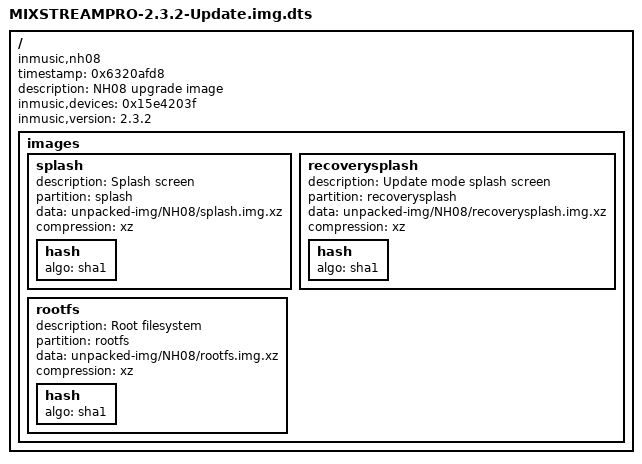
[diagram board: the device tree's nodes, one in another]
/dts-v1/;

/ {
	timestamp = <0x6320afd8>;
	description = "NH08 upgrade image";
	compatible = "inmusic,nh08";
	inmusic,devices = <0x15e4203f>;
	inmusic,version = "2.3.2";

	images {

		splash {
			description = "Splash screen";
			partition = "splash";
			data = /incbin/("unpacked-img/NH08/splash.img.xz");
			compression = "xz";

			hash {
				algo = "sha1";
			};
		};

		recoverysplash {
			description = "Update mode splash screen";
			partition = "recoverysplash";
			data = /incbin/("unpacked-img/NH08/recoverysplash.img.xz");
			compression = "xz";

			hash {
				algo = "sha1";
			};
		};

		rootfs {
			description = "Root filesystem";
			partition = "rootfs";
			data = /incbin/("unpacked-img/NH08/rootfs.img.xz");
			compression = "xz";

			hash {
				algo = "sha1";
			};
		};
	};
};
